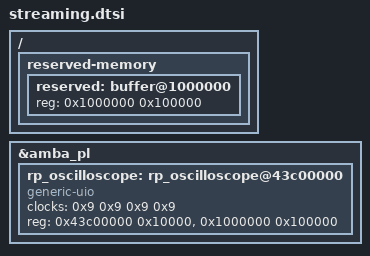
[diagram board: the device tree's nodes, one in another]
/ {
  	fragment@uio {
		target = <&amba_pl>;
                __overlay__ {

                        rp_oscilloscope: rp_oscilloscope@43c00000 {
                     		#address-cells = <1>;
                		#size-cells = <1>;
                                clock-names = "clk", "s_axi_reg_aclk", "m_axi_osc1_aclk", "m_axi_osc2_aclk";
                                clocks = <0x9 0x9 0x9 0x9>;
                                compatible = "generic-uio";
                                reg = <0x43c00000 0x10000>,<0x1000000 0x100000>;
                                       reg-names = "regset", "buffer";
                        };
                        
                };

        };
        fragment@0 {
                target-path = "/";
                __overlay__ {
                reserved-memory {
                        #address-cells = <1>;
                        #size-cells = <1>; 
                        ranges;
                        
                                reserved: buffer@1000000 {
                                reg = <0x1000000 0x100000>;
                                };
                        };
                };
        };
};

